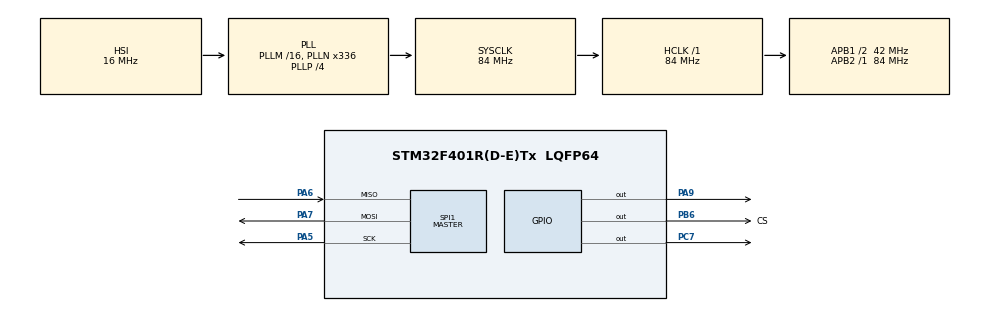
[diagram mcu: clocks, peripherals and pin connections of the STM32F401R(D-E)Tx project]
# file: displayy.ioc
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Mcu.Family=STM32F4
Mcu.Name=STM32F401R(D-E)Tx
Mcu.Package=LQFP64
NVIC.PriorityGroup=NVIC_PRIORITYGROUP_4
NVIC.SPI1_IRQn=true\:0\:0\:false\:false\:true\:true\:true\:true
PA5.Mode=Full_Duplex_Master
PA5.Signal=SPI1_SCK
PA6.Mode=Full_Duplex_Master
PA6.Signal=SPI1_MISO
PA7.Mode=Full_Duplex_Master
PA7.Signal=SPI1_MOSI
PA9.Signal=GPIO_Output
PB6.GPIO_Label=CS
PB6.Signal=GPIO_Output
PC7.Signal=GPIO_Output
ProjectManager.HeapSize=0x200
ProjectManager.StackSize=0x400
ProjectManager.TargetToolchain=STM32CubeIDE
RCC.48MHZClocksFreq_Value=48000000
RCC.AHBFreq_Value=84000000
RCC.APB1CLKDivider=RCC_HCLK_DIV2
RCC.APB1Freq_Value=42000000
RCC.APB1TimFreq_Value=84000000
RCC.APB2Freq_Value=84000000
RCC.APB2TimFreq_Value=84000000
RCC.CortexFreq_Value=84000000
RCC.HCLKFreq_Value=84000000
RCC.HSE_VALUE=8000000
RCC.HSI_VALUE=16000000
RCC.PLLN=336
RCC.PLLP=RCC_PLLP_DIV4
RCC.PLLQ=7
RCC.SYSCLKFreq_VALUE=84000000
RCC.SYSCLKSource=RCC_SYSCLKSOURCE_PLLCLK
RCC.VCOOutputFreq_Value=336000000
SPI1.BaudRatePrescaler=SPI_BAUDRATEPRESCALER_16
SPI1.Direction=SPI_DIRECTION_2LINES
SPI1.Mode=SPI_MODE_MASTER
SPI1.VirtualType=VM_MASTER
board=NUCLEO-F401RE

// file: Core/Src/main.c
/* USER CODE BEGIN Header */
/**
  ******************************************************************************
  * @file           : main.c
  * @brief          : Main program body
  ******************************************************************************
  * @attention
  *
  * <h2><center>&copy; Copyright (c) 2020 STMicroelectronics.
  * All rights reserved.</center></h2>
  *
  * This software component is licensed by ST under BSD 3-Clause license,
  * the "License"; You may not use this file except in compliance with the
  * License. You may obtain a copy of the License at:
  *                        opensource.org/licenses/BSD-3-Clause
  *
  ******************************************************************************
  */
/* USER CODE END Header */
#include "main.h"

/* USER CODE BEGIN Includes */
#include "ST7735.h"
#include "GFX_FUNCTIONS.h"

#include "ambedkar.h"
/* USER CODE END Includes */

SPI_HandleTypeDef hspi1;

void SystemClock_Config(void);
static void MX_GPIO_Init(void);
static void MX_SPI1_Init(void);

int main(void)
{

  /* MCU Configuration--------------------------------------------------------*/

  /* Reset of all peripherals, Initializes the Flash interface and the Systick. */
  HAL_Init();

  /* Configure the system clock */
  SystemClock_Config();

  /* Initialize all configured peripherals */
  MX_GPIO_Init();
  MX_SPI1_Init();
  /* USER CODE BEGIN 2 */

  ST7735_Init(0);
  fillScreen(BLACK);
//  testAll();

  /* USER CODE END 2 */

  /* Infinite loop */
  while (1)
  {

    /* USER CODE BEGIN 3 */

	  ST7735_DrawImage(0,0,64,96,ambedkar_map);
  }
  /* USER CODE END 3 */
}

void SystemClock_Config(void)
{
  RCC_OscInitTypeDef RCC_OscInitStruct = {0};
  RCC_ClkInitTypeDef RCC_ClkInitStruct = {0};

  /** Configure the main internal regulator output voltage
  */
  __HAL_RCC_PWR_CLK_ENABLE();
  __HAL_PWR_VOLTAGESCALING_CONFIG(PWR_REGULATOR_VOLTAGE_SCALE2);

  /** Initializes the RCC Oscillators according to the specified parameters
  * in the RCC_OscInitTypeDef structure.
  */
  RCC_OscInitStruct.OscillatorType = RCC_OSCILLATORTYPE_HSI;
  RCC_OscInitStruct.HSIState = RCC_HSI_ON;
  RCC_OscInitStruct.HSICalibrationValue = RCC_HSICALIBRATION_DEFAULT;
  RCC_OscInitStruct.PLL.PLLState = RCC_PLL_ON;
  RCC_OscInitStruct.PLL.PLLSource = RCC_PLLSOURCE_HSI;
  RCC_OscInitStruct.PLL.PLLM = 16;
  RCC_OscInitStruct.PLL.PLLN = 336;
  RCC_OscInitStruct.PLL.PLLP = RCC_PLLP_DIV4;
  RCC_OscInitStruct.PLL.PLLQ = 7;
  if (HAL_RCC_OscConfig(&RCC_OscInitStruct) != HAL_OK)
  {
    Error_Handler();
  }

  /** Initializes the CPU, AHB and APB buses clocks
  */
  RCC_ClkInitStruct.ClockType = RCC_CLOCKTYPE_HCLK|RCC_CLOCKTYPE_SYSCLK
                              |RCC_CLOCKTYPE_PCLK1|RCC_CLOCKTYPE_PCLK2;
  RCC_ClkInitStruct.SYSCLKSource = RCC_SYSCLKSOURCE_PLLCLK;
  RCC_ClkInitStruct.AHBCLKDivider = RCC_SYSCLK_DIV1;
  RCC_ClkInitStruct.APB1CLKDivider = RCC_HCLK_DIV2;
  RCC_ClkInitStruct.APB2CLKDivider = RCC_HCLK_DIV1;

  if (HAL_RCC_ClockConfig(&RCC_ClkInitStruct, FLASH_LATENCY_2) != HAL_OK)
  {
    Error_Handler();
  }
}

static void MX_SPI1_Init(void)
{

  /* SPI1 parameter configuration*/
  hspi1.Instance = SPI1;
  hspi1.Init.Mode = SPI_MODE_MASTER;
  hspi1.Init.Direction = SPI_DIRECTION_2LINES;
  hspi1.Init.DataSize = SPI_DATASIZE_8BIT;
  hspi1.Init.CLKPolarity = SPI_POLARITY_LOW;
  hspi1.Init.CLKPhase = SPI_PHASE_1EDGE;
  hspi1.Init.NSS = SPI_NSS_SOFT;
  hspi1.Init.BaudRatePrescaler = SPI_BAUDRATEPRESCALER_16;
  hspi1.Init.FirstBit = SPI_FIRSTBIT_MSB;
  hspi1.Init.TIMode = SPI_TIMODE_DISABLE;
  hspi1.Init.CRCCalculation = SPI_CRCCALCULATION_DISABLE;
  hspi1.Init.CRCPolynomial = 10;
  if (HAL_SPI_Init(&hspi1) != HAL_OK)
  {
    Error_Handler();
  }

}

static void MX_GPIO_Init(void)
{
  GPIO_InitTypeDef GPIO_InitStruct = {0};

  /* GPIO Ports Clock Enable */
  __HAL_RCC_GPIOA_CLK_ENABLE();
  __HAL_RCC_GPIOC_CLK_ENABLE();
  __HAL_RCC_GPIOB_CLK_ENABLE();

  /*Configure GPIO pin Output Level */
  HAL_GPIO_WritePin(GPIOC, GPIO_PIN_7, GPIO_PIN_RESET);

  /*Configure GPIO pin Output Level */
  HAL_GPIO_WritePin(GPIOA, GPIO_PIN_9, GPIO_PIN_RESET);

  /*Configure GPIO pin Output Level */
  HAL_GPIO_WritePin(CS_GPIO_Port, CS_Pin, GPIO_PIN_RESET);

  /*Configure GPIO pin : PC7 */
  GPIO_InitStruct.Pin = GPIO_PIN_7;
  GPIO_InitStruct.Mode = GPIO_MODE_OUTPUT_PP;
  GPIO_InitStruct.Pull = GPIO_NOPULL;
  GPIO_InitStruct.Speed = GPIO_SPEED_FREQ_LOW;
  HAL_GPIO_Init(GPIOC, &GPIO_InitStruct);

  /*Configure GPIO pin : PA9 */
  GPIO_InitStruct.Pin = GPIO_PIN_9;
  GPIO_InitStruct.Mode = GPIO_MODE_OUTPUT_PP;
  GPIO_InitStruct.Pull = GPIO_NOPULL;
  GPIO_InitStruct.Speed = GPIO_SPEED_FREQ_LOW;
  HAL_GPIO_Init(GPIOA, &GPIO_InitStruct);

  /*Configure GPIO pin : CS_Pin */
  GPIO_InitStruct.Pin = CS_Pin;
  GPIO_InitStruct.Mode = GPIO_MODE_OUTPUT_PP;
  GPIO_InitStruct.Pull = GPIO_NOPULL;
  GPIO_InitStruct.Speed = GPIO_SPEED_FREQ_LOW;
  HAL_GPIO_Init(CS_GPIO_Port, &GPIO_InitStruct);

}

void Error_Handler(void)
{
}
